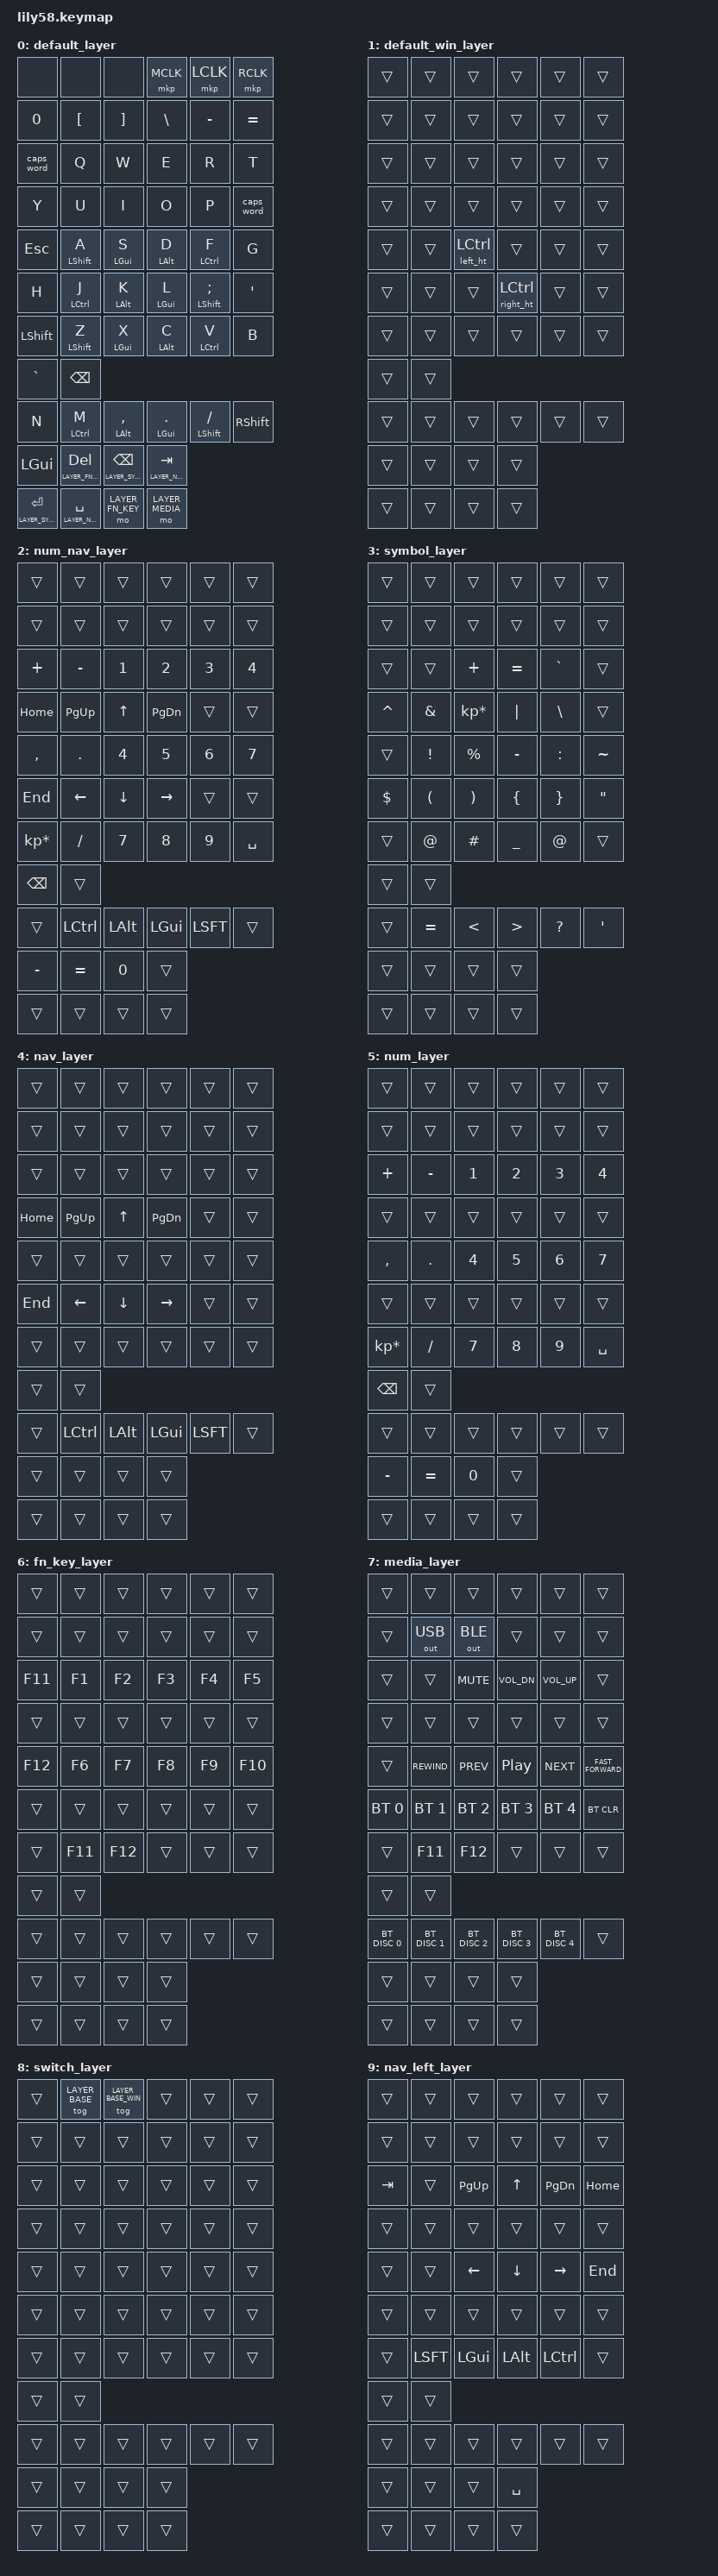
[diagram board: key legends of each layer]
/*
 * Copyright (c) 2020 The ZMK Contributors
 *
 * SPDX-License-Identifier: MIT
 */

#include <behaviors.dtsi>
#include <dt-bindings/zmk/keys.h>
#include <dt-bindings/zmk/bt.h>
#include <dt-bindings/zmk/outputs.h>
#include <dt-bindings/zmk/mouse.h>

#define LAYER_BASE 0
#define LAYER_BASE_WIN 1
#define LAYER_NUM_NAV 2
#define LAYER_SYMBOL 3
#define LAYER_NAV 4
#define LAYER_NUM 5
#define LAYER_FN_KEY 6
#define LAYER_MEDIA 7
#define LAYER_SWITCH 8
#define LAYER_NAV_LEFT 9

#define HOMEY_HOLDING_TYPE "balanced"
#define HOMEY_HOLDING_TIME 200
#define HOMEY_REPEAT_DECAY 200
#define HOMEY_STREAK_DECAY 0
#define COMBO_TIMEOUT 50

// 0  1  2  3  4  5       |      6  7  8  9  10 11
// 12 13 14 15 16 17      |      18 19 20 21 22 23
// 24 25 26 27 28 29      |      30 31 32 33 34 35
// 36 37 38 39 40 41  42  |  43  44 45 46 47 48 49
//         50 51 52 53    |    54 55 56 57

#define LEFT_HAND_KEYS \
    0 1 2 3 4 5 \
    12 13 14 15 16 17 \
    24 25 26 27 28 29 \
    36 37 38 39 40 41

#define RIGHT_HAND_KEYS \
    6 7 8 9 10 11 \
    18 19 20 21 22 23 \
    30 31 32 33 34 35 \
    44 45 46 47 48 49

#define THUMB_KEYS \
    50 51 52 53 \
    54 55 56 57 \
    42 43


/ {

    combos {
        compatible = "zmk,combos";

        combo_grave {
            timeout-ms = <COMBO_TIMEOUT>;
            key-positions = <16 28>; // F + R
            bindings = <&kp GRAVE>;
            layers = <LAYER_BASE>;
        };

        combo_left_bracket {
            timeout-ms = <COMBO_TIMEOUT>;
            key-positions = <19 31>; // U + J
            bindings = <&kp LEFT_BRACKET>;
            layers = <LAYER_BASE>;
        };

        combo_right_bracket {
            timeout-ms = <COMBO_TIMEOUT>;
            key-positions = <20 32>; // I + K
            bindings = <&kp RIGHT_BRACKET>;
            layers = <LAYER_BASE>;
        };

        combo_backslash {
            timeout-ms = <COMBO_TIMEOUT>;
            key-positions = <21 33>; // O + L
            bindings = <&kp BACKSLASH>;
            layers = <LAYER_BASE>;
        };

        combo_nav_left_on {
            timeout-ms = <COMBO_TIMEOUT>;
            key-positions = <50 51>; // bottom left corner
            bindings = <&to LAYER_NAV_LEFT>;
            layers = <LAYER_BASE>;
        };

        combo_nav_left_off {
            timeout-ms = <COMBO_TIMEOUT>;
            key-positions = <50 51>; // bottom left corner
            bindings = <&to LAYER_BASE>;
            layers = <LAYER_NAV_LEFT>;
        };

        // TODO fix this layer
        // combo_switch_layer {
        //     timeout-ms = <COMBO_TIMEOUT>;
        //     key-positions = <56 57>; // RHS fn layer + media layer
        //     bindings = <&mo LAYER_SWITCH>;
        // };
    };

    keymap {
        compatible = "zmk,keymap";

        default_layer {
            bindings = <
/* Number Row */
&none &none &none &mkp MCLK &mkp LCLK &mkp RCLK
&kp N0 &kp LEFT_BRACKET &kp RIGHT_BRACKET &kp BACKSLASH &kp MINUS &kp EQUAL
/* Qwerty Row */
&caps_word &kp Q &kp W &kp E &kp R &kp T
&kp Y &kp U &kp I &kp O &kp P &caps_word
/* Home Row */
&kp ESC &left_ht LSHFT A &left_ht LGUI S &left_ht LALT D &left_ht LCTRL F &kp G // hold-preferred on A has too many false positives
&kp H &right_ht LCTRL J &right_ht LALT K &right_ht LGUI L &right_agg_ht LSHFT SEMI &kp SQT
/* Zxcv Row (Left) */
&kp LSHFT &left_nav_ht LSHFT Z &left_nav_ht LGUI X &left_nav_ht LALT C &left_nav_ht LCTRL V &kp B
/* Middle Buttons */
&kp GRAVE &kp BSPC
/* Zxcv Row (Right) */
&kp N &right_num_ht LCTRL M &right_num_ht LALT COMMA &right_num_ht LGUI DOT &right_num_ht LSHFT FSLH &kp RSHFT
/* Bottom Row */
&kp LGUI &lt LAYER_FN_KEY DEL &agg_lt LAYER_SYMBOL BSPC &agg_lt LAYER_NUM_NAV TAB
&agg_lt LAYER_SYMBOL RET &lt LAYER_NUM_NAV SPACE &mo LAYER_FN_KEY &mo LAYER_MEDIA
            >;
        };

        // TODO right hand not replaced correctly? opt -> ctrl
        // replace HRM GUI with CTRL
        default_win_layer {
            bindings = <
/* Number Row */
&trans &trans &trans &trans &trans &trans
&trans &trans &trans &trans &trans &trans
/* Qwerty Row */
&trans &trans &trans &trans &trans &trans
&trans &trans &trans &trans &trans &trans
/* Home Row */
&trans &trans &left_ht LCTRL &trans &trans &trans
&trans &trans &trans &right_ht LCTRL &trans &trans
/* Zxcv Row (Left) */
&trans &trans &trans &trans &trans &trans
/* Middle Buttons */
&trans &trans
/* Zxcv Row (Right) */
&trans &trans &trans &trans &trans &trans
/* Bottom Row */
&trans &trans &trans &trans
&trans &trans &trans &trans
            >;
        };

        num_nav_layer {
            bindings = <
/* Number Row */
&trans &trans &trans &trans &trans &trans
&trans &trans &trans &trans &trans &trans
/* Qwerty Row */
&kp PLUS &kp MINUS &kp N1 &kp N2 &kp N3 &kp N4
&kp HOME &kp PG_UP &kp UP &kp PG_DN &trans &trans
/* Home Row */
&kp COMMA &kp DOT &kp N4 &kp N5 &kp N6 &kp N7
&kp END &kp LEFT &kp DOWN &kp RIGHT &trans &trans
/* Zxcv Row (Left) */
&kp KP_MULTIPLY &kp FSLH &kp N7 &kp N8 &kp N9 &kp SPACE
/* Middle Buttons */
&kp BSPC &trans
/* Zxcv Row (Right) */
&trans &kp LCTRL &kp LALT &kp LGUI &kp LSFT &trans
/* Bottom Row */
&kp MINUS &kp EQUAL &kp N0 &trans
&trans &trans &trans &trans
            >;
        };

        symbol_layer {
            bindings = <
/* Number Row */
&trans &trans &trans &trans &trans &trans
&trans &trans &trans &trans &trans &trans
/* Qwerty Row */
&trans &trans &kp PLUS &kp EQUAL &kp GRAVE &trans
&kp CARET &kp AMPERSAND &kp KP_MULTIPLY &kp PIPE &kp BACKSLASH &trans
/* Home Row */
&trans &kp EXCL &kp PERCENT &kp MINUS &kp COLON &kp TILDE
&kp DOLLAR &kp LEFT_PARENTHESIS &kp RIGHT_PARENTHESIS &kp LEFT_BRACE &kp RIGHT_BRACE &kp DOUBLE_QUOTES
/* Zxcv Row (Left) */
&trans &kp AT &kp HASH &kp UNDERSCORE &kp AT &trans
/* Middle Buttons */
&trans &trans
/* Zxcv Row (Right) */
&trans &kp EQUAL &kp LT &kp GT &kp QUESTION &kp SINGLE_QUOTE
/* Bottom Row */
&trans &trans &trans &trans
&trans &trans &trans &trans
            >;
        };

        nav_layer {
            bindings = <
/* Number Row */
&trans &trans &trans &trans &trans &trans
&trans &trans &trans &trans &trans &trans
/* Qwerty Row */
&trans &trans &trans &trans &trans &trans
&kp HOME &kp PG_UP &kp UP &kp PG_DN &trans &trans
/* Home Row */
&trans &trans &trans &trans &trans &trans
&kp END &kp LEFT &kp DOWN &kp RIGHT &trans &trans
/* Zxcv Row (Left) */
&trans &trans &trans &trans &trans &trans
/* Middle Buttons */
&trans &trans
/* Zxcv Row (Right) */
&trans &kp LCTRL &kp LALT &kp LGUI &kp LSFT &trans
/* Bottom Row */
&trans &trans &trans &trans
&trans &trans &trans &trans
            >;
        };

        num_layer {
            bindings = <
/* Number Row */
&trans &trans &trans &trans &trans &trans
&trans &trans &trans &trans &trans &trans
/* Qwerty Row */
&kp PLUS &kp MINUS &kp N1 &kp N2 &kp N3 &kp N4
&trans &trans &trans &trans &trans &trans
/* Home Row */
&kp COMMA &kp DOT &kp N4 &kp N5 &kp N6 &kp N7
&trans &trans &trans &trans &trans &trans
/* Zxcv Row (Left) */
&kp KP_MULTIPLY &kp FSLH &kp N7 &kp N8 &kp N9 &kp SPACE
/* Middle Buttons */
&kp BSPC &trans
/* Zxcv Row (Right) */
&trans &trans &trans &trans &trans &trans
/* Bottom Row */
&kp MINUS &kp EQUAL &kp N0 &trans
&trans &trans &trans &trans
            >;
        };

        fn_key_layer {
            bindings = <
/* Number Row */
&trans &trans &trans &trans &trans &trans
&trans &trans &trans &trans &trans &trans
/* Qwerty Row */
&kp F11 &kp F1 &kp F2 &kp F3 &kp F4 &kp F5
&trans &trans &trans &trans &trans &trans
/* Home Row */
&kp F12 &kp F6 &kp F7 &kp F8 &kp F9 &kp F10
&trans &trans &trans &trans &trans &trans
/* Zxcv Row (Left) */
&trans &kp F11 &kp F12 &trans &trans &trans
/* Middle Buttons */
&trans &trans
/* Zxcv Row (Right) */
&trans &trans &trans &trans &trans &trans
/* Bottom Row */
&trans &trans &trans &trans
&trans &trans &trans &trans
            >;
        };

        media_layer {
            bindings = <
/* Number Row */
&trans &trans &trans &trans &trans &trans
&trans &out OUT_USB &out OUT_BLE &trans &trans &trans
/* Qwerty Row */
&trans &trans &kp C_MUTE &kp C_VOL_DN &kp C_VOL_UP &trans
&trans &trans &trans &trans &trans &trans
/* Home Row */
&trans &kp C_REWIND &kp C_PREV &kp C_PLAY_PAUSE &kp C_NEXT &kp C_FAST_FORWARD
&bt BT_SEL 0 &bt BT_SEL 1 &bt BT_SEL 2 &bt BT_SEL 3 &bt BT_SEL 4 &bt BT_CLR
/* Zxcv Row (Left) */
&trans &kp F11 &kp F12 &trans &trans &trans
/* Middle Buttons */
&trans &trans
/* Zxcv Row (Right) */
&bt BT_DISC 0 &bt BT_DISC 1 &bt BT_DISC 2 &bt BT_DISC 3 &bt BT_DISC 4 &trans
/* Bottom Row */
&trans &trans &trans &trans
&trans &trans &trans &trans
            >;
        };

        switch_layer {
            bindings = <
/* Number Row */
&trans &tog LAYER_BASE &tog LAYER_BASE_WIN &trans &trans &trans
&trans &trans &trans &trans &trans &trans
/* Qwerty Row */
&trans &trans &trans &trans &trans &trans
&trans &trans &trans &trans &trans &trans
/* Home Row */
&trans &trans &trans &trans &trans &trans
&trans &trans &trans &trans &trans &trans
/* Zxcv Row (Left) */
&trans &trans &trans &trans &trans &trans
/* Middle Buttons */
&trans &trans
/* Zxcv Row (Right) */
&trans &trans &trans &trans &trans &trans
/* Bottom Row */
&trans &trans &trans &trans
&trans &trans &trans &trans
            >;
        };

        nav_left_layer {
            bindings = <
/* Number Row */
&trans &trans &trans &trans &trans &trans
&trans &trans &trans &trans &trans &trans
/* Qwerty Row */
&kp TAB &trans &kp PG_UP &kp UP &kp PG_DN &kp HOME
&trans &trans &trans &trans &trans &trans
/* Home Row */
&trans &trans &kp LEFT &kp DOWN &kp RIGHT &kp END
&trans &trans &trans &trans &trans &trans
/* Zxcv Row (Left) */
&trans &kp LSFT &kp LGUI &kp LALT &kp LCTRL &trans
/* Middle Buttons */
&trans &trans
/* Zxcv Row (Right) */
&trans &trans &trans &trans &trans &trans
/* Bottom Row */
&trans &trans &trans &kp SPACE
&trans &trans &trans &trans
            >;
        };

    };

    behaviors {
        left_ht: left_hold_tap {
            compatible = "zmk,behavior-hold-tap";
            flavor = HOMEY_HOLDING_TYPE;
            hold-trigger-key-positions = <RIGHT_HAND_KEYS THUMB_KEYS>;
            hold-trigger-on-release; // wait for other home row mods
            // hold-while-undecided;
            tapping-term-ms = <HOMEY_HOLDING_TIME>;
            quick-tap-ms = <HOMEY_REPEAT_DECAY>;
            require-prior-idle-ms = <HOMEY_STREAK_DECAY>;
            #binding-cells = <2>;
            bindings = <&kp>, <&kp>;
        };

        left_agg_ht: left_aggressive_hold_tap {
            compatible = "zmk,behavior-hold-tap";
            flavor = "hold-preferred";
            hold-trigger-key-positions = <RIGHT_HAND_KEYS THUMB_KEYS>;
            // hold-trigger-on-release; // will cause hold-trigger-key-positions to be ignored for hold-preferred flavour
            // hold-while-undecided;
            tapping-term-ms = <HOMEY_HOLDING_TIME>;
            quick-tap-ms = <HOMEY_REPEAT_DECAY>;
            require-prior-idle-ms = <HOMEY_STREAK_DECAY>;
            #binding-cells = <2>;
            bindings = <&kp>, <&kp>;
        };

        right_ht: right_hold_tap {
            compatible = "zmk,behavior-hold-tap";
            flavor = HOMEY_HOLDING_TYPE;
            hold-trigger-key-positions = <LEFT_HAND_KEYS THUMB_KEYS>;
            hold-trigger-on-release; // wait for other home row mods
            // hold-while-undecided;
            tapping-term-ms = <HOMEY_HOLDING_TIME>;
            quick-tap-ms = <HOMEY_REPEAT_DECAY>;
            require-prior-idle-ms = <HOMEY_STREAK_DECAY>;
            #binding-cells = <2>;
            bindings = <&kp>, <&kp>;
        };

        right_agg_ht: right_aggressive_hold_tap {
            compatible = "zmk,behavior-hold-tap";
            flavor = "hold-preferred";
            hold-trigger-key-positions = <LEFT_HAND_KEYS THUMB_KEYS>;
            // hold-trigger-on-release; // will cause hold-trigger-key-positions to be ignored for hold-preferred flavour
            // hold-while-undecided;
            tapping-term-ms = <HOMEY_HOLDING_TIME>;
            quick-tap-ms = <HOMEY_REPEAT_DECAY>;
            require-prior-idle-ms = <HOMEY_STREAK_DECAY>;
            #binding-cells = <2>;
            bindings = <&kp>, <&kp>;
        };

        left_nav_ht: left_nav_hold_tap {
            compatible = "zmk,behavior-hold-tap";
            flavor = "tap-preferred";
            hold-trigger-key-positions = <RIGHT_HAND_KEYS THUMB_KEYS>;
            hold-trigger-on-release; // wait for other home row mods
            tapping-term-ms = <HOMEY_HOLDING_TIME>;
            quick-tap-ms = <HOMEY_REPEAT_DECAY>;
            require-prior-idle-ms = <HOMEY_STREAK_DECAY>;
            #binding-cells = <2>;
            bindings = <&lm_nav>, <&kp>;
        };

        right_num_ht: right_num_hold_tap {
            compatible = "zmk,behavior-hold-tap";
            flavor = "tap-preferred";
            hold-trigger-key-positions = <LEFT_HAND_KEYS THUMB_KEYS>;
            hold-trigger-on-release; // wait for other home row mods
            tapping-term-ms = <HOMEY_HOLDING_TIME>;
            quick-tap-ms = <HOMEY_REPEAT_DECAY>;
            require-prior-idle-ms = <HOMEY_STREAK_DECAY>;
            #binding-cells = <2>;
            bindings = <&lm_num>, <&kp>;
        };

        agg_lt: aggresive_layer_tap {
            compatible = "zmk,behavior-hold-tap";
            flavor = "hold-preferred";
            tapping-term-ms = <200>;
            quick-tap-ms = <200>;
            #binding-cells = <2>;
            bindings = <&mo>, <&kp>;
        };

    };

    macros {
        /**
        * Temporarily switches to a layer (`&mo`) while a modifier is held.
        * Analogous to QMK's `LM()`, using a parameterized macro.
        *
        * Params:
        *  1. Layer to switch to
        *  2. Modifier to press while layer is active
        *
        * Example:
        *  `&lm NUM_LAYER LSHIFT`
        */
        lm: lm {
            compatible = "zmk,behavior-macro-two-param";
            wait-ms = <0>;
            tap-ms = <0>;
            #binding-cells = <2>;
            bindings
                = <&macro_param_1to1>
                , <&macro_press &mo MACRO_PLACEHOLDER>
                , <&macro_param_2to1>
                , <&macro_press &kp MACRO_PLACEHOLDER>
                , <&macro_pause_for_release>
                , <&macro_param_2to1>
                , <&macro_release &kp MACRO_PLACEHOLDER>
                , <&macro_param_1to1>
                , <&macro_release &mo MACRO_PLACEHOLDER>
                ;
        };

        lm_nav: lm_nav {
            compatible = "zmk,behavior-macro-one-param";
            wait-ms = <0>;
            tap-ms = <0>;
            #binding-cells = <1>;
            bindings
                = <&macro_param_1to2>
                , <&macro_press &lm LAYER_NAV MACRO_PLACEHOLDER>
                , <&macro_pause_for_release>
                , <&macro_release &lm LAYER_NAV MACRO_PLACEHOLDER>
                ;
        };

        lm_num: lm_num {
            compatible = "zmk,behavior-macro-one-param";
            wait-ms = <0>;
            tap-ms = <0>;
            #binding-cells = <1>;
            bindings
                = <&macro_param_1to2>
                , <&macro_press &lm LAYER_NUM MACRO_PLACEHOLDER>
                , <&macro_pause_for_release>
                , <&macro_release &lm LAYER_NUM MACRO_PLACEHOLDER>
                ;
        };
    };

};
